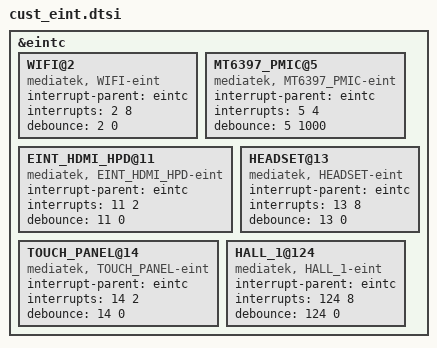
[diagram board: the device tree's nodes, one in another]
/*
 * Generated by MTK SP Drv_CodeGen Version 03.13.6  for MT8173. Copyright MediaTek Inc. (C) 2013.
 * Mon Nov 10 18:25:54 2014
 * Do Not Modify the File.
 */

/*************************
 * EINT DTSI File
*************************/

&eintc {
	WIFI@2 {
		compatible = "mediatek, WIFI-eint";
		interrupt-parent = <&eintc>;
		interrupts = <2 8>;
		debounce = <2 0>;
	};

	MT6397_PMIC@5 {
		compatible = "mediatek, MT6397_PMIC-eint";
		interrupt-parent = <&eintc>;
		interrupts = <5 4>;
		debounce = <5 1000>;
	};

	EINT_HDMI_HPD@11 {
		compatible = "mediatek, EINT_HDMI_HPD-eint";
		interrupt-parent = <&eintc>;
		interrupts = <11 2>;
		debounce = <11 0>;
	};

	HEADSET@13 {
		compatible = "mediatek, HEADSET-eint";
		interrupt-parent = <&eintc>;
		interrupts = <13 8>;
		debounce = <13 0>;
	};

	TOUCH_PANEL@14 {
		compatible = "mediatek, TOUCH_PANEL-eint";
		interrupt-parent = <&eintc>;
		interrupts = <14 2>;
		debounce = <14 0>;
	};

	HALL_1@124 {
		compatible = "mediatek, HALL_1-eint";
		interrupt-parent = <&eintc>;
		interrupts = <124 8>;
		debounce = <124 0>;
	};

};
